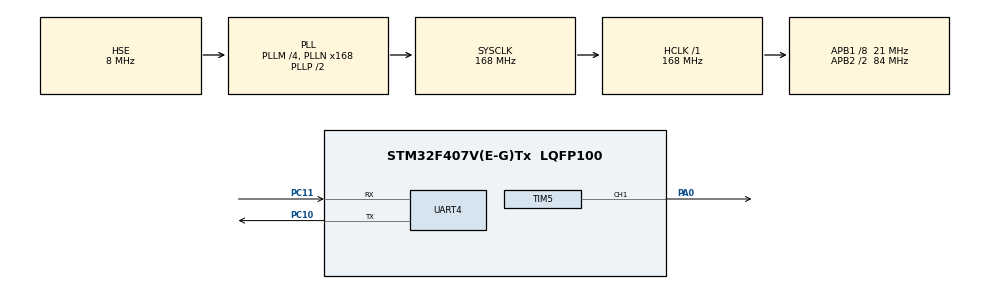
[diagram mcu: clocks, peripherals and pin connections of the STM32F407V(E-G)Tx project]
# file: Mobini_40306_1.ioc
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Mcu.Family=STM32F4
Mcu.Name=STM32F407V(E-G)Tx
Mcu.Package=LQFP100
NVIC.PriorityGroup=NVIC_PRIORITYGROUP_4
NVIC.UART4_IRQn=true\:0\:0\:false\:false\:true\:true\:true\:true
PA0-WKUP.Signal=S_TIM5_CH1
PC10.Mode=Asynchronous
PC10.Signal=UART4_TX
PC11.Mode=Asynchronous
PC11.Signal=UART4_RX
PH0-OSC_IN.Mode=HSE-External-Oscillator
PH0-OSC_IN.Signal=RCC_OSC_IN
PH1-OSC_OUT.Mode=HSE-External-Oscillator
PH1-OSC_OUT.Signal=RCC_OSC_OUT
ProjectManager.HeapSize=0x200
ProjectManager.StackSize=0x400
ProjectManager.TargetToolchain=MDK-ARM V5.32
RCC.48MHZClocksFreq_Value=84000000
RCC.AHBFreq_Value=168000000
RCC.APB1CLKDivider=RCC_HCLK_DIV8
RCC.APB1Freq_Value=21000000
RCC.APB1TimFreq_Value=42000000
RCC.APB2CLKDivider=RCC_HCLK_DIV2
RCC.APB2Freq_Value=84000000
RCC.APB2TimFreq_Value=168000000
RCC.CortexFreq_Value=168000000
RCC.HCLKFreq_Value=168000000
RCC.HSE_VALUE=8000000
RCC.HSI_VALUE=16000000
RCC.LSE_VALUE=32768
RCC.PLLM=4
RCC.PLLN=168
RCC.PLLSourceVirtual=RCC_PLLSOURCE_HSE
RCC.SYSCLKFreq_VALUE=168000000
RCC.SYSCLKSource=RCC_SYSCLKSOURCE_PLLCLK
RCC.VCOOutputFreq_Value=336000000
SH.S_TIM5_CH1.0=TIM5_CH1,PWM Generation1 CH1
TIM5.Channel-PWM\ Generation1\ CH1=TIM_CHANNEL_1
TIM5.Period=999999
TIM5.Prescaler=83
TIM5.Pulse-PWM\ Generation1\ CH1=500000
UART4.VirtualMode=Asynchronous
VP_TIM5_VS_ClockSourceINT.Mode=Internal
board=custom

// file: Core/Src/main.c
/* USER CODE BEGIN Header */
/**
 ******************************************************************************
 * @file           : main.c
 * @brief          : Main program body
 ******************************************************************************
 * @attention
 *
 * Copyright (c) 2025 STMicroelectronics.
 * All rights reserved.
 *
 * This software is licensed under terms that can be found in the LICENSE file
 * in the root directory of this software component.
 * If no LICENSE file comes with this software, it is provided AS-IS.
 *
 ******************************************************************************
 */
/* USER CODE END Header */
#include "main.h"

/* USER CODE BEGIN Includes */
#include <stdio.h>
#include <stdlib.h>
#include <stm32f407xx.h>
#include <string.h>
/* USER CODE END Includes */

TIM_HandleTypeDef htim5;

UART_HandleTypeDef huart4;

/* USER CODE BEGIN PV */
uint8_t UART4_rxBuffer[4] = { 0 };

/* USER CODE END PV */

void SystemClock_Config(void);
static void MX_GPIO_Init(void);
static void MX_UART4_Init(void);
static void MX_TIM5_Init(void);

/* USER CODE BEGIN 0 */
void HAL_UART_RxCpltCallback(UART_HandleTypeDef* huart)
{
	HAL_UART_Transmit(&huart4, UART4_rxBuffer, 4, 100);
	HAL_UART_Receive_IT(&huart4, UART4_rxBuffer, 4);
	TIM5->CCR1 = atoi(UART4_rxBuffer) * 10000;
}
/* USER CODE END 0 */

int main(void)
{
	/* USER CODE BEGIN 1 */
	// sprintf(UART4_rxBuffer, "danial\n");

	/* USER CODE END 1 */

	/* MCU Configuration--------------------------------------------------------*/

	/* Reset of all peripherals, Initializes the Flash interface and the Systick. */
	HAL_Init();

	/* Configure the system clock */
	SystemClock_Config();

	/* Initialize all configured peripherals */
	MX_GPIO_Init();
	MX_UART4_Init();
	MX_TIM5_Init();
	/* USER CODE BEGIN 2 */
	HAL_TIM_Base_Start(&htim5);
	HAL_TIM_PWM_Start(&htim5, TIM_CHANNEL_1);

	HAL_UART_Receive_IT(&huart4, UART4_rxBuffer, 4);

	/* USER CODE END 2 */

	/* Infinite loop */
	/* USER CODE BEGIN WHILE */
	while (1)
	{
		// HAL_UART_Receive(&huart4, UART4_rxBuffer, 3, 1000);
		// HAL_UART_Transmit(&huart4, UART4_rxBuffer, 3, 100);
		// TIM5->CCR2 = atoi(UART4_rxBuffer) * 1000000;

		/* USER CODE END WHILE */

	}
}

void SystemClock_Config(void)
{
	RCC_OscInitTypeDef RCC_OscInitStruct = { 0 };
	RCC_ClkInitTypeDef RCC_ClkInitStruct = { 0 };

	/** Configure the main internal regulator output voltage
	 */
	__HAL_RCC_PWR_CLK_ENABLE();
	__HAL_PWR_VOLTAGESCALING_CONFIG(PWR_REGULATOR_VOLTAGE_SCALE1);

	/** Initializes the RCC Oscillators according to the specified parameters
	 * in the RCC_OscInitTypeDef structure.
	 */
	RCC_OscInitStruct.OscillatorType = RCC_OSCILLATORTYPE_HSE;
	RCC_OscInitStruct.HSEState = RCC_HSE_ON;
	RCC_OscInitStruct.PLL.PLLState = RCC_PLL_ON;
	RCC_OscInitStruct.PLL.PLLSource = RCC_PLLSOURCE_HSE;
	RCC_OscInitStruct.PLL.PLLM = 4;
	RCC_OscInitStruct.PLL.PLLN = 168;
	RCC_OscInitStruct.PLL.PLLP = RCC_PLLP_DIV2;
	RCC_OscInitStruct.PLL.PLLQ = 4;
	if (HAL_RCC_OscConfig(&RCC_OscInitStruct) != HAL_OK)
	{
		Error_Handler();
	}

	/** Initializes the CPU, AHB and APB buses clocks
	 */
	RCC_ClkInitStruct.ClockType = RCC_CLOCKTYPE_HCLK | RCC_CLOCKTYPE_SYSCLK
		| RCC_CLOCKTYPE_PCLK1 | RCC_CLOCKTYPE_PCLK2;
	RCC_ClkInitStruct.SYSCLKSource = RCC_SYSCLKSOURCE_PLLCLK;
	RCC_ClkInitStruct.AHBCLKDivider = RCC_SYSCLK_DIV1;
	RCC_ClkInitStruct.APB1CLKDivider = RCC_HCLK_DIV8;
	RCC_ClkInitStruct.APB2CLKDivider = RCC_HCLK_DIV2;

	if (HAL_RCC_ClockConfig(&RCC_ClkInitStruct, FLASH_LATENCY_5) != HAL_OK)
	{
		Error_Handler();
	}
}

static void MX_TIM5_Init(void)
{

	TIM_ClockConfigTypeDef sClockSourceConfig = { 0 };
	TIM_MasterConfigTypeDef sMasterConfig = { 0 };
	TIM_OC_InitTypeDef sConfigOC = { 0 };

	htim5.Instance = TIM5;
	htim5.Init.Prescaler = 83;
	htim5.Init.CounterMode = TIM_COUNTERMODE_UP;
	htim5.Init.Period = 999999;
	htim5.Init.ClockDivision = TIM_CLOCKDIVISION_DIV1;
	htim5.Init.AutoReloadPreload = TIM_AUTORELOAD_PRELOAD_DISABLE;
	if (HAL_TIM_Base_Init(&htim5) != HAL_OK)
	{
		Error_Handler();
	}
	sClockSourceConfig.ClockSource = TIM_CLOCKSOURCE_INTERNAL;
	if (HAL_TIM_ConfigClockSource(&htim5, &sClockSourceConfig) != HAL_OK)
	{
		Error_Handler();
	}
	if (HAL_TIM_PWM_Init(&htim5) != HAL_OK)
	{
		Error_Handler();
	}
	sMasterConfig.MasterOutputTrigger = TIM_TRGO_RESET;
	sMasterConfig.MasterSlaveMode = TIM_MASTERSLAVEMODE_DISABLE;
	if (HAL_TIMEx_MasterConfigSynchronization(&htim5, &sMasterConfig) != HAL_OK)
	{
		Error_Handler();
	}
	sConfigOC.OCMode = TIM_OCMODE_PWM1;
	sConfigOC.Pulse = 500000;
	sConfigOC.OCPolarity = TIM_OCPOLARITY_HIGH;
	sConfigOC.OCFastMode = TIM_OCFAST_DISABLE;
	if (HAL_TIM_PWM_ConfigChannel(&htim5, &sConfigOC, TIM_CHANNEL_1) != HAL_OK)
	{
		Error_Handler();
	}
	HAL_TIM_MspPostInit(&htim5);
}

static void MX_UART4_Init(void)
{

	huart4.Instance = UART4;
	huart4.Init.BaudRate = 115200;
	huart4.Init.WordLength = UART_WORDLENGTH_8B;
	huart4.Init.StopBits = UART_STOPBITS_1;
	huart4.Init.Parity = UART_PARITY_NONE;
	huart4.Init.Mode = UART_MODE_TX_RX;
	huart4.Init.HwFlowCtl = UART_HWCONTROL_NONE;
	huart4.Init.OverSampling = UART_OVERSAMPLING_16;
	if (HAL_UART_Init(&huart4) != HAL_OK)
	{
		Error_Handler();
	}
}

static void MX_GPIO_Init(void)
{

	/* GPIO Ports Clock Enable */
	__HAL_RCC_GPIOH_CLK_ENABLE();
	__HAL_RCC_GPIOA_CLK_ENABLE();
	__HAL_RCC_GPIOC_CLK_ENABLE();
}

void Error_Handler(void)
{
	__disable_irq();
	while (1)
	{
	}
}
